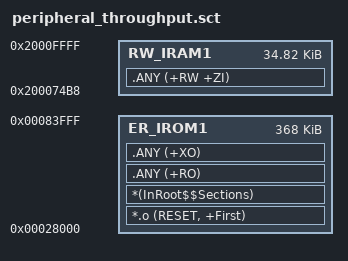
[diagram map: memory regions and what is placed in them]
; *************************************************************
; *** Scatter-Loading Description File generated by uVision ***
; *************************************************************

LR_IROM1 0x00028000 0x0005C000  {    ; load region size_region
  ER_IROM1 0x00028000 0x0005C000  {  ; load address = execution address
   *.o (RESET, +First)
   *(InRoot$$Sections)
   .ANY (+RO)
   .ANY (+XO)
  }
  RW_IRAM1 0x200074B8 0x00008B48  {  ; RW data
   .ANY (+RW +ZI)
  }
}

